# SH30F2xx register map
Vendor: Sino Wealth Electronic Ltd.; Series: SH30Fxxx; File version: 1.0
CPU: CM0+ r0p1, little endian, no MPU, no FPU, 2 interrupt priority bits
Registers are 32-bit, read-write, reset 0x0 unless marked. A register's access mark holds for its fields unless they carry their own. Offsets are from the block's base; [hi:lo] are bit positions; {n}, {i} and the like mark numbered series.

## IWDT
Base 0x40003000
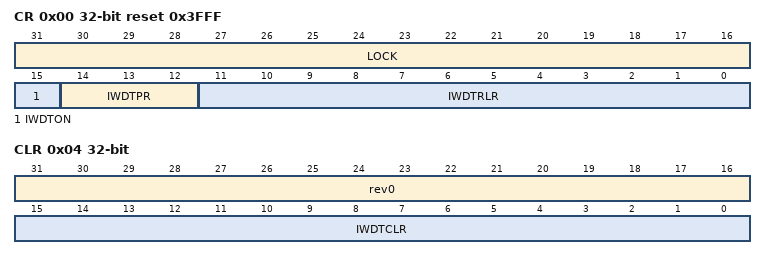
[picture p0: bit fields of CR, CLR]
0x00 CR reset 0x3FFF
  [31:16] LOCK, [15] IWDTON, [14:12] IWDTPR, [11:0] IWDTRLR
0x04 CLR wo
  [31:16] rev0, [15:0] IWDTCLR

## WWDT
Base 0x40003400
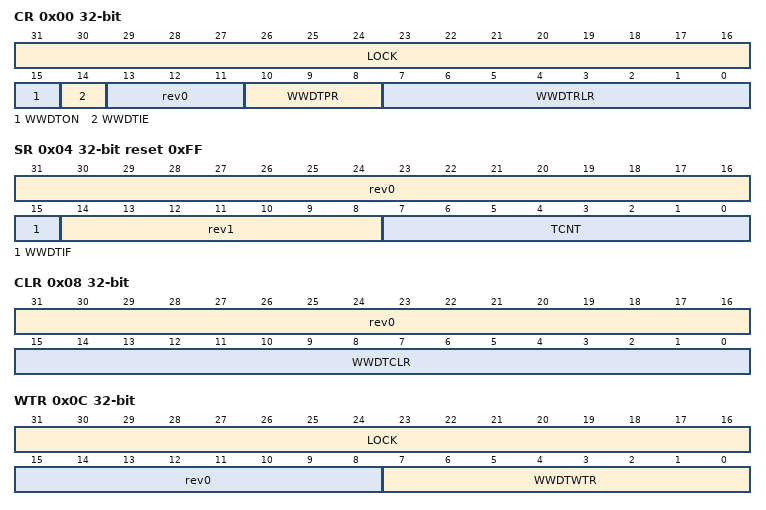
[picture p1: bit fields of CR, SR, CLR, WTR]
0x00 CR
  [31:16] LOCK, [15] WWDTON, [14] WWDTIE, [13:11] rev0, [10:8] WWDTPR, [7:0] WWDTRLR
0x04 SR reset 0xFF
  [31:16] rev0, [15] WWDTIF, [14:8] rev1, [7:0] TCNT ro
0x08 CLR wo
  [31:16] rev0, [15:0] WWDTCLR
0x0C WTR
  [31:16] LOCK, [15:8] rev0, [7:0] WWDTWTR

## AMOC
Base 0x40003800
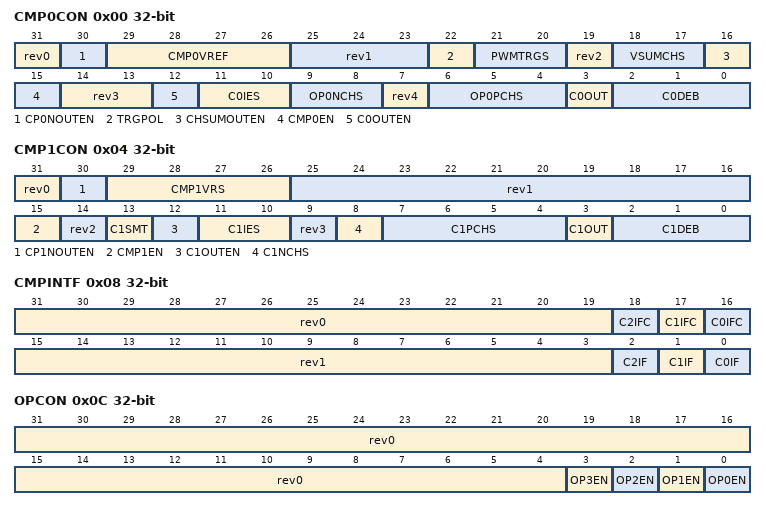
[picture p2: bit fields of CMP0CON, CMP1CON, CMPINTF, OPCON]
0x00 CMP0CON
  [31] rev0, [30] CP0NOUTEN, [29:26] CMP0VREF, [25:23] rev1, [22] TRGPOL, [21:20] PWMTRGS, [19] rev2, [18:17] VSUMCHS, [16] CHSUMOUTEN, [15] CMP0EN, [14:13] rev3, [12] C0OUTEN, [11:10] C0IES, [9:8] OP0NCHS, [7] rev4, [6:4] OP0PCHS, [3] C0OUT ro, [2:0] C0DEB
0x04 CMP1CON
  [31] rev0, [30] CP1NOUTEN, [29:26] CMP1VRS, [25:16] rev1, [15] CMP1EN, [14] rev2, [13] C1SMT, [12] C1OUTEN, [11:10] C1IES, [9] rev3, [8] C1NCHS, [7:4] C1PCHS, [3] C1OUT ro, [2:0] C1DEB
0x08 CMPINTF
  [31:19] rev0, [18] C2IFC, [17] C1IFC, [16] C0IFC, [15:3] rev1, [2] C2IF ro, [1] C1IF ro, [0] C0IF ro
0x0C OPCON
  [31:4] rev0, [n] OP{n}EN (n=0..3)
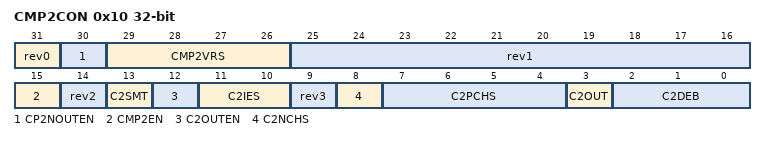
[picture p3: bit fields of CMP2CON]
0x10 CMP2CON
  [31] rev0, [30] CP2NOUTEN, [29:26] CMP2VRS, [25:16] rev1, [15] CMP2EN, [14] rev2, [13] C2SMT, [12] C2OUTEN, [11:10] C2IES, [9] rev3, [8] C2NCHS, [7:4] C2PCHS, [3] C2OUT ro, [2:0] C2DEB

## EXTI
Base 0x40004000
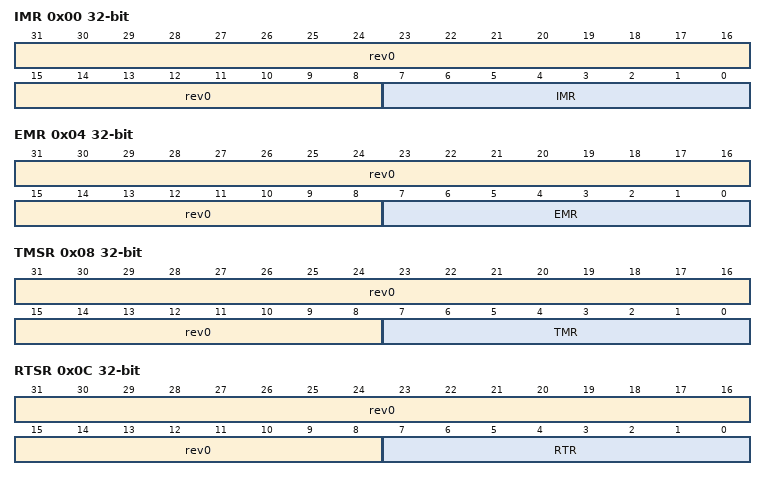
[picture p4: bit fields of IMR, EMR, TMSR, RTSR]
0x00 IMR
  [31:8] rev0, [7:0] IMR
0x04 EMR
  [31:8] rev0, [7:0] EMR
0x08 TMSR
  [31:8] rev0, [7:0] TMR
0x0C RTSR
  [31:8] rev0, [7:0] RTR
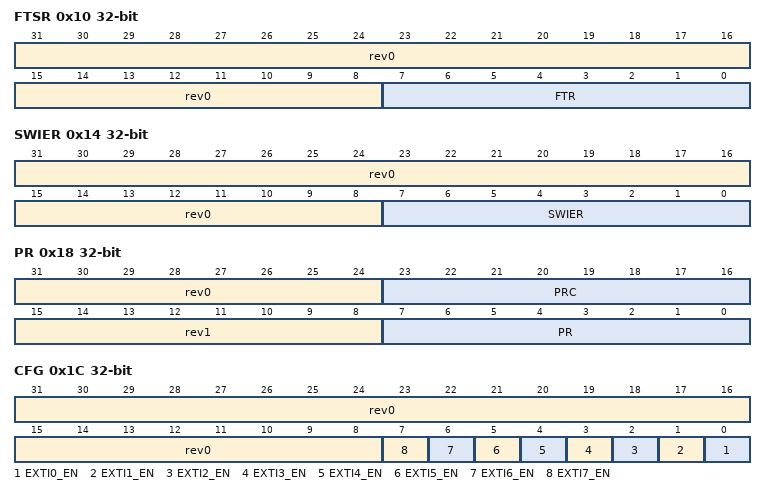
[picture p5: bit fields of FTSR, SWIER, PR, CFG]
0x10 FTSR
  [31:8] rev0, [7:0] FTR
0x14 SWIER wo
  [31:8] rev0, [7:0] SWIER
0x18 PR
  [31:24] rev0, [23:16] PRC, [15:8] rev1, [7:0] PR ro
0x1C CFG
  [31:8] rev0, [n] EXTI{n}_EN (n=0..7)
0x20 CFGH
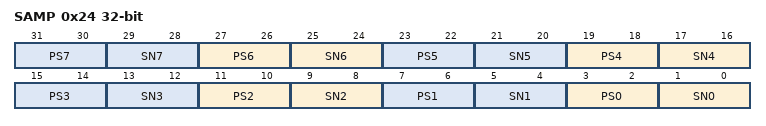
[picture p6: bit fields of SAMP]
0x24 SAMP
  [4n+3:4n+2] PS{n} (n=0..7), [4n+1:4n] SN{n} (n=0..7)

## PWM3
Base 0x40005000
Same registers: PWM4 0x40005400
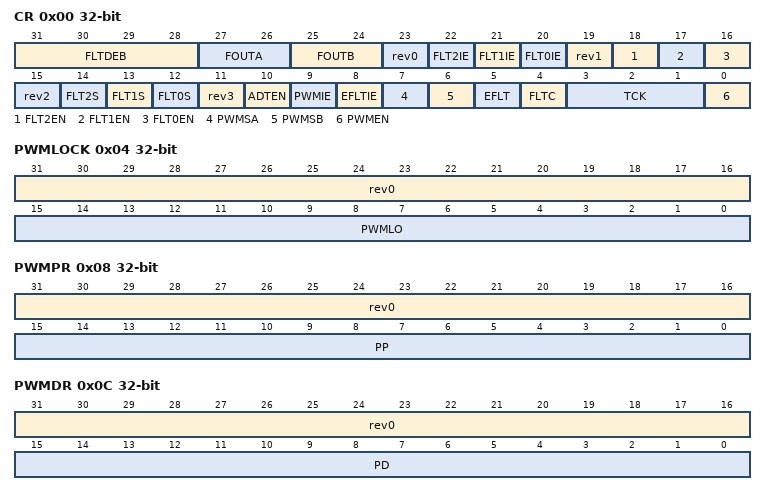
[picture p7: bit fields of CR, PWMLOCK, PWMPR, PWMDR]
0x00 CR
  [31:28] FLTDEB, [27:26] FOUTA, [25:24] FOUTB, [23-4n] rev{n} (n=0..3), [22] FLT2IE, [21] FLT1IE, [20] FLT0IE, [18] FLT2EN, [17] FLT1EN, [16] FLT0EN, [14] FLT2S, [13] FLT1S, [12] FLT0S, [10] ADTEN, [9] PWMIE, [8] EFLTIE, [7] PWMSA, [6] PWMSB, [5] EFLT, [4] FLTC, [3:1] TCK, [0] PWMEN
0x04 PWMLOCK
  [31:16] rev0, [15:0] PWMLO
0x08 PWMPR
  [31:16] rev0, [15:0] PP
0x0C PWMDR
  [31:16] rev0, [15:0] PD
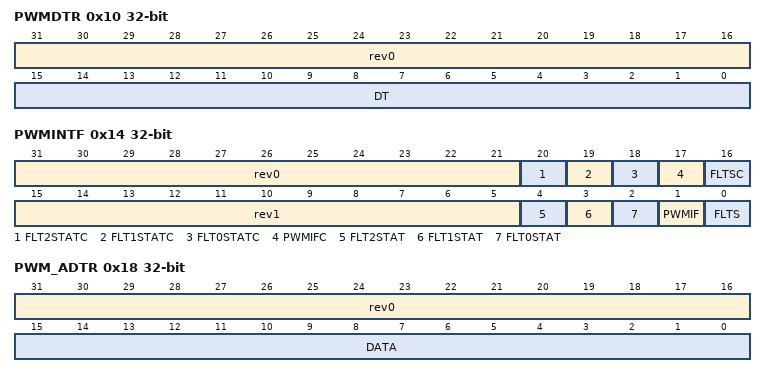
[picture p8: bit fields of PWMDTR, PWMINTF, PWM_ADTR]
0x10 PWMDTR
  [31:16] rev0, [15:0] DT
0x14 PWMINTF
  [31:21] rev0, [20] FLT2STATC, [19] FLT1STATC, [18] FLT0STATC, [17] PWMIFC, [16] FLTSC, [15:5] rev1, [4] FLT2STAT ro, [3] FLT1STAT ro, [2] FLT0STAT ro, [1] PWMIF ro, [0] FLTS ro
0x18 PWM_ADTR
  [31:16] rev0, [15:0] DATA

## GPIOA
Base 0x40040000
Same registers: GPIOB 0x40040080, GPIOC 0x40040100
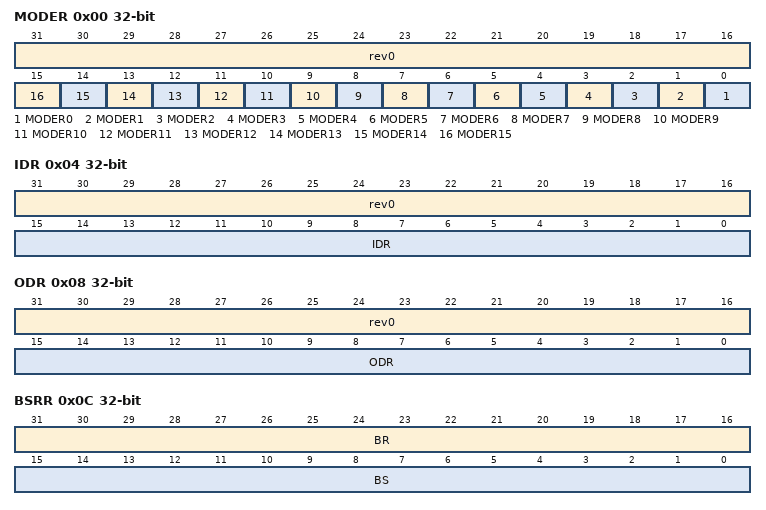
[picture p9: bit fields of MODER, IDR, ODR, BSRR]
0x00 MODER
  [31:16] rev0, [n] MODER{n} (n=0..15)
0x04 IDR ro
  [31:16] rev0 rw, [15:0] IDR
0x08 ODR
  [31:16] rev0, [15:0] ODR
0x0C BSRR
  [31:16] BR, [15:0] BS
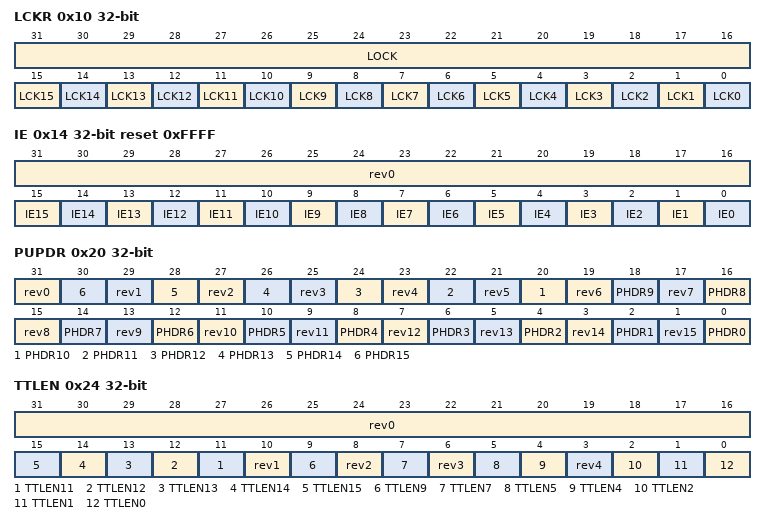
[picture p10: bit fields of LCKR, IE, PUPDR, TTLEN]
0x10 LCKR
  [31:16] LOCK, [n] LCK{n} (n=0..15)
0x14 IE reset 0xFFFF
  [31:16] rev0, [n] IE{n} (n=0..15)
0x18 OTYPER
0x1C ODRVR
0x20 PUPDR
  [31-2n] rev{n} (n=0..15), [2n] PHDR{n} (n=0..15)
0x24 TTLEN
  [31:16] rev0, [n] TTLEN{n} (n=11..15), [10] rev1, [9] TTLEN9, [8] rev2, [7] TTLEN7, [6] rev3, [5] TTLEN5, [4] TTLEN4, [3] rev4, [2] TTLEN2, [1] TTLEN1, [0] TTLEN0
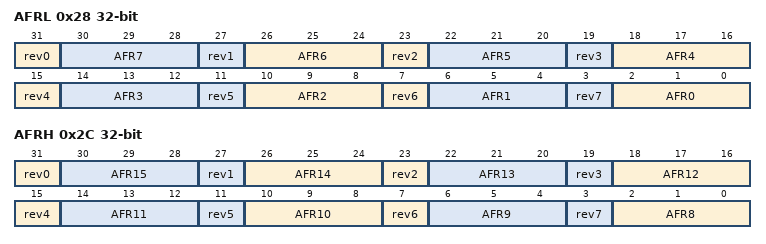
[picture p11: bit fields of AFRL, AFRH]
0x28 AFRL
  [31-4n] rev{n} (n=0..7), [4n+2:4n] AFR{n} (n=0..7)
0x2C AFRH
  [31-4n] rev{n} (n=0..7), [4n-30:4n-32] AFR{n} (n=8..15)

## MCM
Base 0x40040400
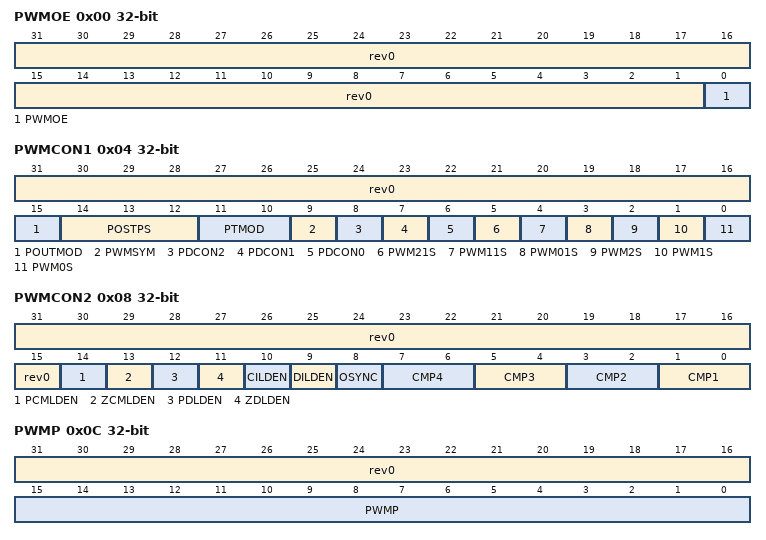
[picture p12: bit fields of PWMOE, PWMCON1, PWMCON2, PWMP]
0x00 PWMOE
  [31:1] rev0, [0] PWMOE
0x04 PWMCON1
  [31:16] rev0, [15] POUTMOD, [14:12] POSTPS, [11:10] PTMOD, [9] PWMSYM, [8] PDCON2, [7] PDCON1, [6] PDCON0, [5] PWM21S, [4] PWM11S, [3] PWM01S, [2] PWM2S, [1] PWM1S, [0] PWM0S
0x08 PWMCON2
  [31:15] rev0, [14] PCMLDEN, [13] ZCMLDEN, [12] PDLDEN, [11] ZDLDEN, [10] CILDEN, [9] DILDEN, [8] OSYNC, [2n-1:2n-2] CMP{n} (n=1..4)
0x0C PWMP
  [31:16] rev0, [15:0] PWMP
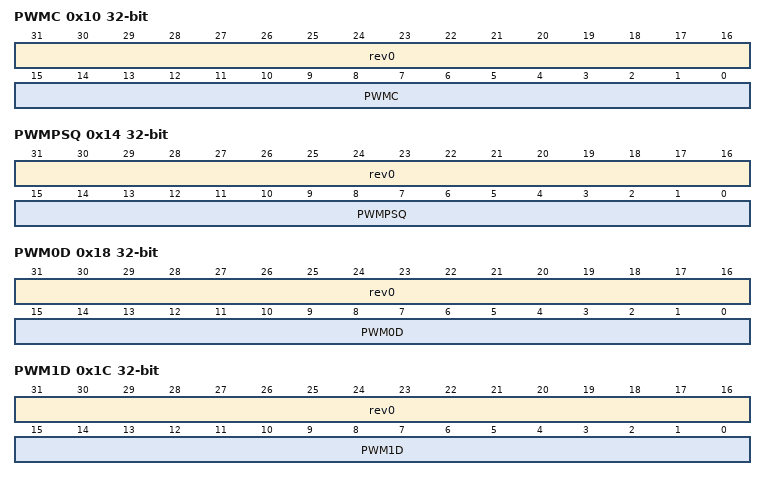
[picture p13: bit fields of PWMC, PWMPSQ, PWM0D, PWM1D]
0x10 PWMC
  [31:16] rev0, [15:0] PWMC
0x14 PWMPSQ
  [31:16] rev0, [15:0] PWMPSQ
0x18 PWM0D
  [31:16] rev0, [15:0] PWM0D
0x1C PWM1D
  [31:16] rev0, [15:0] PWM1D
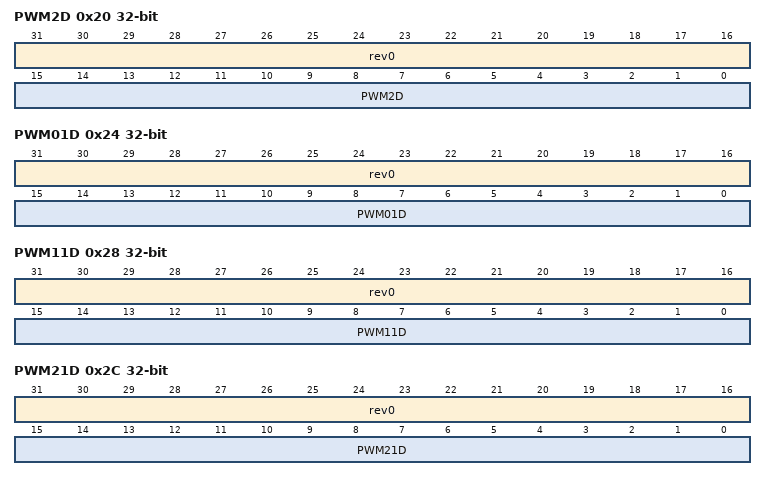
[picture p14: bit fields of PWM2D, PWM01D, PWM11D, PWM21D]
0x20 PWM2D
  [31:16] rev0, [15:0] PWM2D
0x24 PWM01D
  [31:16] rev0, [15:0] PWM01D
0x28 PWM11D
  [31:16] rev0, [15:0] PWM11D
0x2C PWM21D
  [31:16] rev0, [15:0] PWM21D
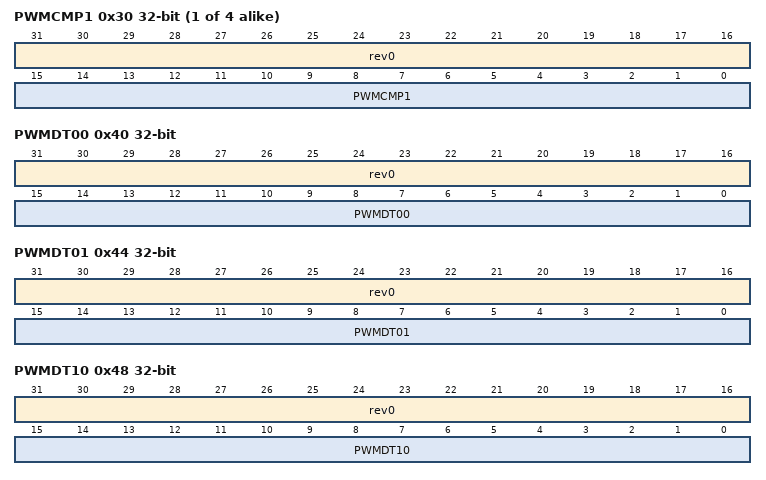
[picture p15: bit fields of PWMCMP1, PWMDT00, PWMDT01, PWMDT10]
{0x2C+4i} PWMCMP{i} (i=1..4)
  [31:16] rev0, [15:0] PWMCMP{i}
0x40 PWMDT00
  [31:16] rev0, [15:0] PWMDT00
0x44 PWMDT01
  [31:16] rev0, [15:0] PWMDT01
0x48 PWMDT10
  [31:16] rev0, [15:0] PWMDT10
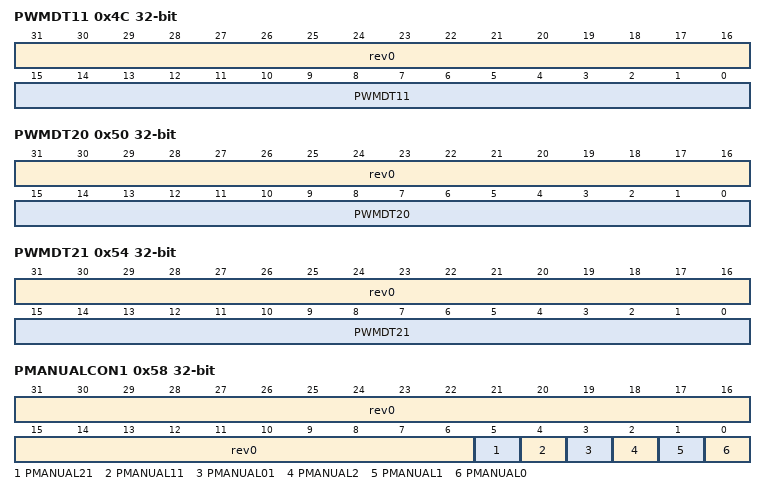
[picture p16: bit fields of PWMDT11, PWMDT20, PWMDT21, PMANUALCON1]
0x4C PWMDT11
  [31:16] rev0, [15:0] PWMDT11
0x50 PWMDT20
  [31:16] rev0, [15:0] PWMDT20
0x54 PWMDT21
  [31:16] rev0, [15:0] PWMDT21
0x58 PMANUALCON1
  [31:6] rev0, [5] PMANUAL21, [4] PMANUAL11, [3] PMANUAL01, [2] PMANUAL2, [1] PMANUAL1, [0] PMANUAL0
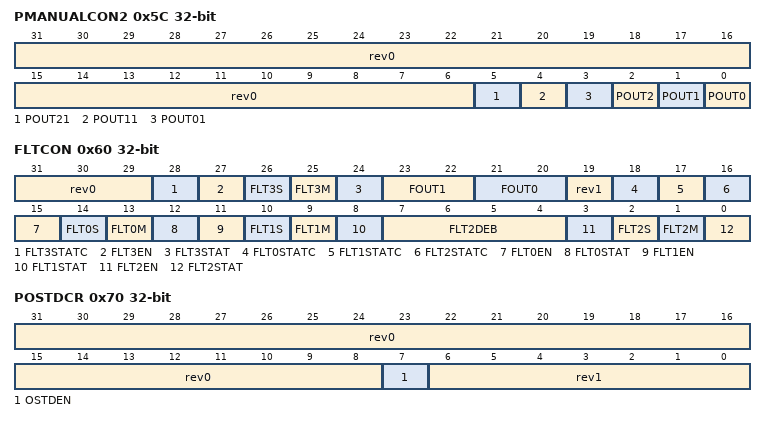
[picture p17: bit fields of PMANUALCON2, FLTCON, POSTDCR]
0x5C PMANUALCON2
  [31:6] rev0, [5] POUT21, [4] POUT11, [3] POUT01, [2] POUT2, [1] POUT1, [0] POUT0
0x60 FLTCON
  [31:29] rev0, [28] FLT3STATC, [27] FLT3EN, [26] FLT3S, [25] FLT3M, [24] FLT3STAT ro, [23:22] FOUT1, [21:20] FOUT0, [19] rev1, [18] FLT0STATC, [17] FLT1STATC, [16] FLT2STATC, [15] FLT0EN, [14] FLT0S, [13] FLT0M, [12] FLT0STAT ro, [11] FLT1EN, [10] FLT1S, [9] FLT1M, [8] FLT1STAT ro, [7:4] FLT2DEB, [3] FLT2EN, [2] FLT2S, [1] FLT2M, [0] FLT2STAT ro
0x70 POSTDCR
  [31:8] rev0, [7] OSTDEN, [6:0] rev1
0x74 PWMINTEN
  [31:14] rev0, [13] FLTCMP2IE, [12] OSTDIE, [11] rev1, [10] FLTCMP1IE, [9] FLTCMP0IE, [8] FLTIE, [7] PWMPIE, [6] PWMZIE, [5] PTDD2IE, [4] PTUD2IE, [3] PTDD1IE, [2] PTUD1IE, [1] PTDD0IE, [0] PTUD0IE
0x78 PWMINTF
  [31:30] rev0, [29] FLTCMP2IFC, [28] OSTDFC, [27] rev1, [26] FLTCMP1IFC, [25] FLTCMP0IFC, [24] FLTIFC, [23] PWMPIFC, [22] PWMZIFC, [21] PTDD2IFC, [20] PTUD2IFC, [19] PTDD1IFC, [18] PTUD1IFC, [17] PTDD0IFC, [16] PTUD0IFC, [15:14] rev2, [13] FLTCMP2IF ro, [12] OSTDF ro, [11] rev3 ro, [10] FLTCMP1IF ro, [9] FLTCMP0IF ro, [8] FLTIF ro, [7] PWMPIF ro, [6] PWMZIF ro, [5] PTDD2IF ro, [4] PTUD2IF ro, [3] PTDD1IF ro, [2] PTUD1IF ro, [1] PTDD0IF ro, [0] PTUD0IF ro
0x7C PWMRLDEN0
  [31:8] rev0, [7:0] PWMRLDEN0
0x80 PWMRLDEN1
  [31:8] rev0, [7:0] PWMRLDEN1
0x84 FLTWEN
  [31:16] rev0, [15:0] FLTWEN
0x88 PWMREMAP
  [31:3] rev0, [2:0] PWMIO
